# Espressif register map
File version: 1.0
CPU: Xtensa LX6 1, little endian, no MPU, FPU, 3 interrupt priority bits
Registers are 32-bit, access not given, reset 0x0 unless marked. A register's access mark holds for its fields unless they carry their own. Offsets are from the block's base; [hi:lo] are bit positions.

## UART
Base 0x3FF40000
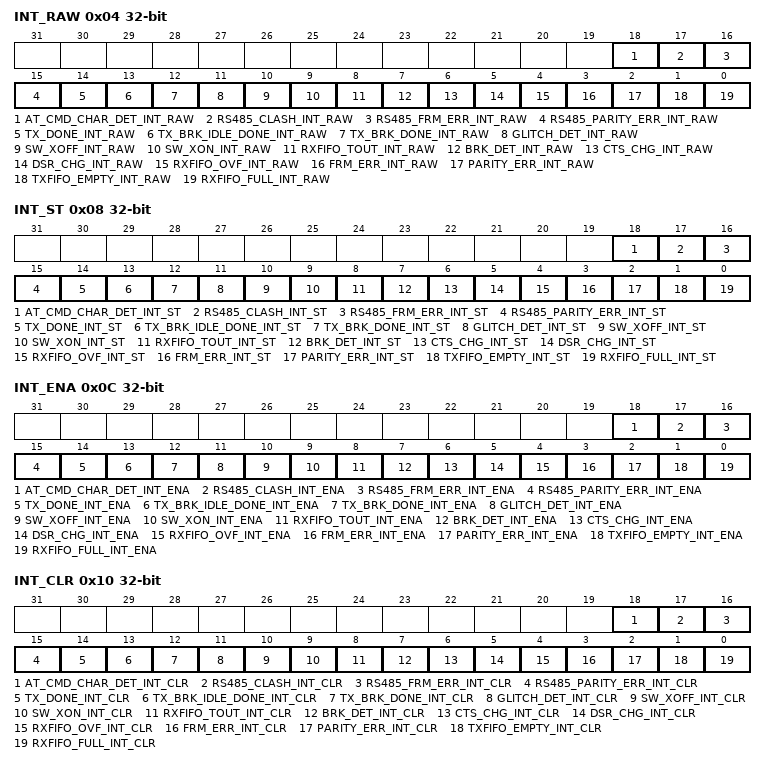
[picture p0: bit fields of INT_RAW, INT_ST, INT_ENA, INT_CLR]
0x04 INT_RAW — UART_INT_RAW
  [18] AT_CMD_CHAR_DET_INT_RAW, [17] RS485_CLASH_INT_RAW, [16] RS485_FRM_ERR_INT_RAW, [15] RS485_PARITY_ERR_INT_RAW, [14] TX_DONE_INT_RAW, [13] TX_BRK_IDLE_DONE_INT_RAW, [12] TX_BRK_DONE_INT_RAW, [11] GLITCH_DET_INT_RAW, [10] SW_XOFF_INT_RAW, [9] SW_XON_INT_RAW, [8] RXFIFO_TOUT_INT_RAW, [7] BRK_DET_INT_RAW, [6] CTS_CHG_INT_RAW, [5] DSR_CHG_INT_RAW, [4] RXFIFO_OVF_INT_RAW, [3] FRM_ERR_INT_RAW, [2] PARITY_ERR_INT_RAW, [1] TXFIFO_EMPTY_INT_RAW, [0] RXFIFO_FULL_INT_RAW
0x08 INT_ST — UART_INT_ST
  [18] AT_CMD_CHAR_DET_INT_ST, [17] RS485_CLASH_INT_ST, [16] RS485_FRM_ERR_INT_ST, [15] RS485_PARITY_ERR_INT_ST, [14] TX_DONE_INT_ST, [13] TX_BRK_IDLE_DONE_INT_ST, [12] TX_BRK_DONE_INT_ST, [11] GLITCH_DET_INT_ST, [10] SW_XOFF_INT_ST, [9] SW_XON_INT_ST, [8] RXFIFO_TOUT_INT_ST, [7] BRK_DET_INT_ST, [6] CTS_CHG_INT_ST, [5] DSR_CHG_INT_ST, [4] RXFIFO_OVF_INT_ST, [3] FRM_ERR_INT_ST, [2] PARITY_ERR_INT_ST, [1] TXFIFO_EMPTY_INT_ST, [0] RXFIFO_FULL_INT_ST
0x0C INT_ENA — UART_INT_ENA
  [18] AT_CMD_CHAR_DET_INT_ENA, [17] RS485_CLASH_INT_ENA, [16] RS485_FRM_ERR_INT_ENA, [15] RS485_PARITY_ERR_INT_ENA, [14] TX_DONE_INT_ENA, [13] TX_BRK_IDLE_DONE_INT_ENA, [12] TX_BRK_DONE_INT_ENA, [11] GLITCH_DET_INT_ENA, [10] SW_XOFF_INT_ENA, [9] SW_XON_INT_ENA, [8] RXFIFO_TOUT_INT_ENA, [7] BRK_DET_INT_ENA, [6] CTS_CHG_INT_ENA, [5] DSR_CHG_INT_ENA, [4] RXFIFO_OVF_INT_ENA, [3] FRM_ERR_INT_ENA, [2] PARITY_ERR_INT_ENA, [1] TXFIFO_EMPTY_INT_ENA, [0] RXFIFO_FULL_INT_ENA
0x10 INT_CLR — UART_INT_CLR
  [18] AT_CMD_CHAR_DET_INT_CLR, [17] RS485_CLASH_INT_CLR, [16] RS485_FRM_ERR_INT_CLR, [15] RS485_PARITY_ERR_INT_CLR, [14] TX_DONE_INT_CLR, [13] TX_BRK_IDLE_DONE_INT_CLR, [12] TX_BRK_DONE_INT_CLR, [11] GLITCH_DET_INT_CLR, [10] SW_XOFF_INT_CLR, [9] SW_XON_INT_CLR, [8] RXFIFO_TOUT_INT_CLR, [7] BRK_DET_INT_CLR, [6] CTS_CHG_INT_CLR, [5] DSR_CHG_INT_CLR, [4] RXFIFO_OVF_INT_CLR, [3] FRM_ERR_INT_CLR, [2] PARITY_ERR_INT_CLR, [1] TXFIFO_EMPTY_INT_CLR, [0] RXFIFO_FULL_INT_CLR
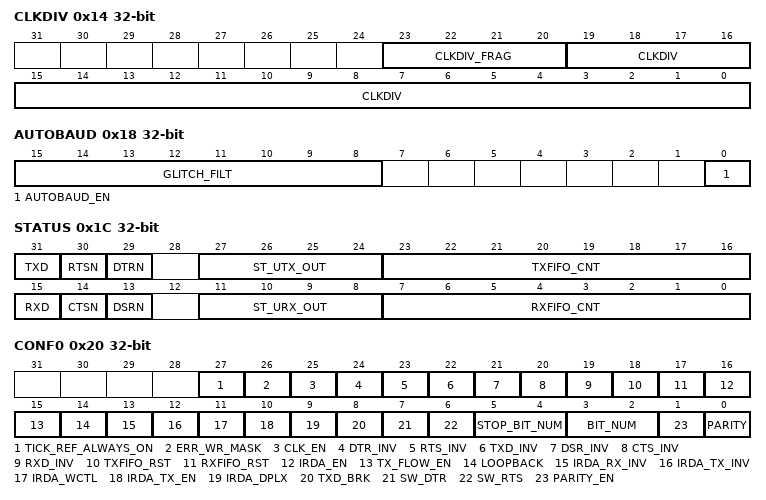
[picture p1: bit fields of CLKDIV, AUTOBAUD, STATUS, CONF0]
0x14 CLKDIV — UART_CLKDIV
  [23:20] CLKDIV_FRAG, [19:0] CLKDIV
0x18 AUTOBAUD — UART_AUTOBAUD
  [15:8] GLITCH_FILT, [0] AUTOBAUD_EN
0x1C STATUS — UART_STATUS
  [31] TXD, [30] RTSN, [29] DTRN, [27:24] ST_UTX_OUT, [23:16] TXFIFO_CNT, [15] RXD, [14] CTSN, [13] DSRN, [11:8] ST_URX_OUT, [7:0] RXFIFO_CNT
0x20 CONF0 — UART_CONF0
  [27] TICK_REF_ALWAYS_ON, [26] ERR_WR_MASK, [25] CLK_EN, [24] DTR_INV, [23] RTS_INV, [22] TXD_INV, [21] DSR_INV, [20] CTS_INV, [19] RXD_INV, [18] TXFIFO_RST, [17] RXFIFO_RST, [16] IRDA_EN, [15] TX_FLOW_EN, [14] LOOPBACK, [13] IRDA_RX_INV, [12] IRDA_TX_INV, [11] IRDA_WCTL, [10] IRDA_TX_EN, [9] IRDA_DPLX, [8] TXD_BRK, [7] SW_DTR, [6] SW_RTS, [5:4] STOP_BIT_NUM, [3:2] BIT_NUM, [1] PARITY_EN, [0] PARITY
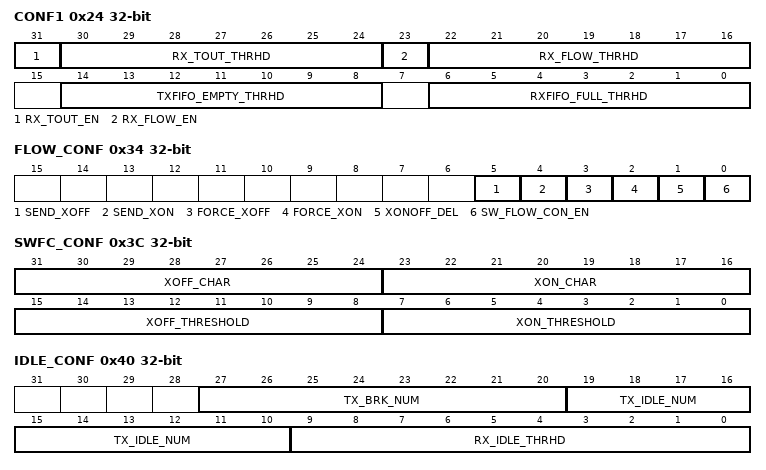
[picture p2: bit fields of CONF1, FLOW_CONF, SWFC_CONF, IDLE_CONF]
0x24 CONF1 — UART_CONF1
  [31] RX_TOUT_EN, [30:24] RX_TOUT_THRHD, [23] RX_FLOW_EN, [22:16] RX_FLOW_THRHD, [14:8] TXFIFO_EMPTY_THRHD, [6:0] RXFIFO_FULL_THRHD
0x28 LOWPULSE — UART_LOWPULSE
  [19:0] LOWPULSE_MIN_CNT
0x2C HIGHPULSE — UART_HIGHPULSE
  [19:0] HIGHPULSE_MIN_CNT
0x30 RXD_CNT — UART_RXD_CNT
  [9:0] RXD_EDGE_CNT
0x34 FLOW_CONF — UART_FLOW_CONF
  [5] SEND_XOFF, [4] SEND_XON, [3] FORCE_XOFF, [2] FORCE_XON, [1] XONOFF_DEL, [0] SW_FLOW_CON_EN
0x38 SLEEP_CONF — UART_SLEEP_CONF
  [9:0] ACTIVE_THRESHOLD
0x3C SWFC_CONF — UART_SWFC_CONF
  [31:24] XOFF_CHAR, [23:16] XON_CHAR, [15:8] XOFF_THRESHOLD, [7:0] XON_THRESHOLD
0x40 IDLE_CONF — UART_IDLE_CONF
  [27:20] TX_BRK_NUM, [19:10] TX_IDLE_NUM, [9:0] RX_IDLE_THRHD
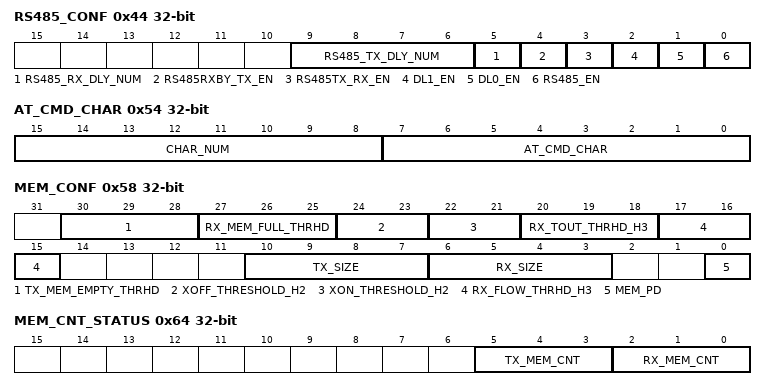
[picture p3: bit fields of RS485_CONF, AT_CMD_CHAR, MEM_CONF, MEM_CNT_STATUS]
0x44 RS485_CONF — UART_RS485_CONF
  [9:6] RS485_TX_DLY_NUM, [5] RS485_RX_DLY_NUM, [4] RS485RXBY_TX_EN, [3] RS485TX_RX_EN, [2] DL1_EN, [1] DL0_EN, [0] RS485_EN
0x48 AT_CMD_PRECNT — UART_AT_CMD_PRECNT
  [23:0] PRE_IDLE_NUM
0x4C AT_CMD_POSTCNT — UART_AT_CMD_POSTCNT
  [23:0] POST_IDLE_NUM
0x50 AT_CMD_GAPTOUT — UART_AT_CMD_GAPTOUT
  [23:0] RX_GAP_TOUT
0x54 AT_CMD_CHAR — UART_AT_CMD_CHAR
  [15:8] CHAR_NUM, [7:0] AT_CMD_CHAR
0x58 MEM_CONF — UART_MEM_CONF
  [30:28] TX_MEM_EMPTY_THRHD, [27:25] RX_MEM_FULL_THRHD, [24:23] XOFF_THRESHOLD_H2, [22:21] XON_THRESHOLD_H2, [20:18] RX_TOUT_THRHD_H3, [17:15] RX_FLOW_THRHD_H3, [10:7] TX_SIZE, [6:3] RX_SIZE, [0] MEM_PD
0x5C MEM_TX_STATUS — UART_MEM_TX_STATUS
  [23:0] MEM_TX_STATUS
0x60 MEM_RX_STATUS — UART_MEM_RX_STATUS
  [23:13] MEM_RX_WR_ADDR, [12:2] MEM_RX_RD_ADDR, [23:0] MEM_RX_STATUS
0x64 MEM_CNT_STATUS — UART_MEM_CNT_STATUS
  [5:3] TX_MEM_CNT, [2:0] RX_MEM_CNT
0x68 POSPULSE — UART_POSPULSE
  [19:0] POSEDGE_MIN_CNT
0x6C NEGPULSE — UART_NEGPULSE
  [19:0] NEGEDGE_MIN_CNT
0x78 DATE — UART_DATE
0x7C ID — UART_ID
